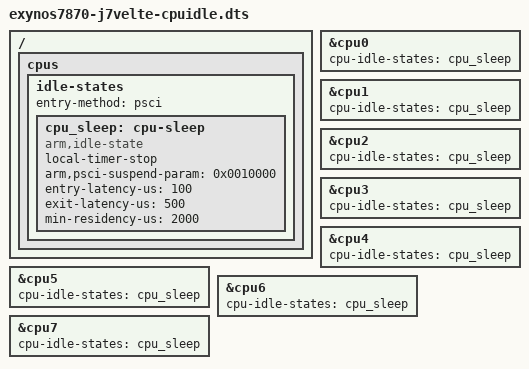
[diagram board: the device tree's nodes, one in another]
// SPDX-License-Identifier: GPL-2.0-only
/* Written by Claude 2026-10-10. Charger tree plus one CPU idle state: core
 * power-down through PSCI CPU_SUSPEND. The suspend parameter is the one the
 * vendor 3.18 device tree uses (exynos7870.dtsi, CPU_SLEEP_BOOT/NONBOOT:
 * 0x0010000); the latencies are deliberately more conservative than the
 * vendor's 35/90/750 us. The vendor kernel also clears the core's PMU
 * CONFIGURATION register before the call (tools/kmod/j701f_cpupd.c does that
 * here). The state is registered switched off
 * (kernel/patches/linux-cpuidle-psci-exynos7870-default-off.patch) and is
 * enabled per core through
 * /sys/devices/system/cpu/cpuN/cpuidle/state1/disable.
 */
#include "exynos7870-j7velte-charger.dts"

/ {
    cpus {
        idle-states {
            entry-method = "psci";

            cpu_sleep: cpu-sleep {
                compatible = "arm,idle-state";
                local-timer-stop;
                arm,psci-suspend-param = <0x0010000>;
                entry-latency-us = <100>;
                exit-latency-us = <500>;
                min-residency-us = <2000>;
            };
        };
    };
};

&cpu0 { cpu-idle-states = <&cpu_sleep>; };
&cpu1 { cpu-idle-states = <&cpu_sleep>; };
&cpu2 { cpu-idle-states = <&cpu_sleep>; };
&cpu3 { cpu-idle-states = <&cpu_sleep>; };
&cpu4 { cpu-idle-states = <&cpu_sleep>; };
&cpu5 { cpu-idle-states = <&cpu_sleep>; };
&cpu6 { cpu-idle-states = <&cpu_sleep>; };
&cpu7 { cpu-idle-states = <&cpu_sleep>; };
